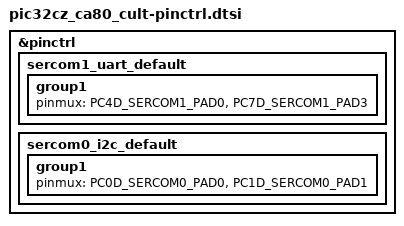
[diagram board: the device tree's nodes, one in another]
/*
 * Copyright (c) 2026 Microchip Technology Inc.
 *
 * SPDX-License-Identifier: Apache-2.0
 */

#include <dt-bindings/pic32c/pic32cz_ca/pic32cz_ca80/pic32cz8110ca80208-pinctrl.h>

&pinctrl {
	sercom1_uart_default: sercom1_uart_default {
		group1 {
			pinmux = <PC4D_SERCOM1_PAD0>,
				 <PC7D_SERCOM1_PAD3>;
		};
	};

	sercom0_i2c_default: sercom0_i2c_default {
		group1 {
			pinmux = <PC0D_SERCOM0_PAD0>,
				 <PC1D_SERCOM0_PAD1>;
		};
	};
};
